# sdmmc_secure register map
Vendor: Texas Instruments
Registers are 32-bit, access per field, reset 0x0 unless marked. A register's access mark holds for its fields unless they carry their own. Offsets are as the file gives them; [hi:lo] are bit positions; {n}, {i} and the like mark numbered series; 'fields as' and 'values as' point back to an identical list.

## sdmmc_secure (part 2 of 2)
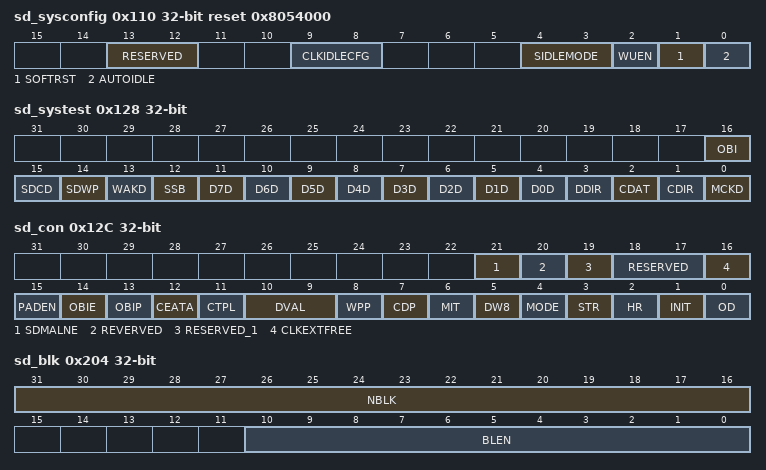
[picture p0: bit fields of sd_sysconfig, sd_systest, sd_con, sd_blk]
0x110 sd_sysconfig reset 0x8054000 (reset mask 0xFFFFC000) — This register allows controlling various parameters of the OCP interface.
  [13:12] RESERVED rw — Host interface power Management, standby/wait control. Note: these bit fields are *not used*, since the IP not support MDMA.
  [9:8] CLKIDLECFG rw — Clock idle policy register, Clocks activity during wake up mode period. Bit8: OCP interface clock Bit9: Functional clock
    0=OFF (Interface and Functional clock may be switched off); 1=INT (Interface clock is maintained. Functional clock may be switched-off.); 2=FUNC (Functional clock is maintained. Interface clock may be switched-off.); 3=ALL (Interface and Functional clocks are maintained.)
  [4:3] SIDLEMODE rw — Power management We are using this register only to change CON.DVAL, else these bit fields are *not used*, since Idle request is not supported.
  [2] WUEN rw — This field controls the wakeup capability of the module.
    0=OFF (Wakeup capability is disabled); 1=EN (Wakeup capability is enabled)
  [1] SOFTRST rw — Software reset. The bit is automatically reset by the hardware. During reset, it always returns 0.
  [0] AUTOIDLE rw — Internal Clock gating strategy 0: Clocks are free-running 1: Automatic clock gating strategy is applied, based on the OCP and MMC interface activity
    0=OFF (Clocks are free-running); 1=ON (Automatic clock gating strategy is applied)
0x114 sd_sysstatus ro — This register provides status information about the module excluding the interrupt status information.
  [0] RSTDONE — Internal Reset Monitoring Note: The debounce clock , the interface clock and the functional clock must be provided to the SDMMC host controller to allow the internal reset monitoring.
    0=ONGOING (Internal module reset is on-going); 1=COMPLETE (Reset completed)
0x124 sd_csre rw — Card Status Response Error Detection This register enables the host controller to detect card status errors of response type R1, R1b for all cards and of R5, R5b and R6 response for cards types SD or SDIO. When a bit SD_SD_CSRE[i] is set to 1, if the corresponding bit at the same position in the response RSP10[i] is set to 1, the host controller indicates a card error (SD_STAT.CERR bit) interrupt status to avoid the host driver reading the response register (RSP10). No automatic card error detection for autoCMD12 is implemented; the host system has to check autoCMD12 response register (RSP76) for possible card errors.
  [31:0] STA — Card status response error
    0=MINIMUM (Minimum value); 0xFFFFFFFF=MAXIMUM (Maximum value)
0x128 sd_systest — SDMMC System Test Register This register is used to control the signals that connect to I/O pins when the module is configured in system test (SD_SYSTEST) mode for boundary connectivity verification. In SD_SYSTEST mode, a write into SD_CMD register will not start a transfer.
  [16] OBI ro — Out-Of-Band Interrupt (OBI) data value Note: Out-Of-Band Interrupt (OBI) is not supported.
  [15] SDCD ro — Card detect input signal (SDCD) data value
    0=LOW (The card detect pin is driven low); 1=HIGH (The card detect pin is driven high)
  [14] SDWP ro — Write protect input signal (SDWP) data value
    0=LOW (The write protect pin SDWP is driven low); 1=HIGH (The write protect pin SDWP is driven high)
  [13] WAKD rw — Wake request output signal data value
    0=LOW (The pin SWAKEUP is driven low); 1=HIGH (The pin SWAKEUP is driven high)
  [12] SSB rw — Set status bit This bit must be cleared prior attempting to clear a status bit of the interrupt status register (SD_STAT).
    0=LOW (Clears this SSB bit field. Writing 0 does not clear already set status bits); 1=HIGH (Force to 1 all status bits of the interrupt status register (SD_STAT) only if the corresponding bit field in the Interrupt signal enable register (SD_ISE) is set.)
  [n+4] D{n}D rw (n=0..7) — DAT{n} input/output signal data value
    0=LOW (If SD_SYSTEST.DDIR bit = 0 (output mode direction), the DAT{n} line is driven low. If SD_SYSTEST.DDIR bit = 1 (input mode direction), no effect.); 1=HIGH (If SD_SYSTEST.DDIR bit = 0 (output mode direction), the DAT{n} line is driven high. If SD_SYSTEST.DDIR bit = 1 (input mode direction), no effect.)
  [3] DDIR rw — Control of the DAT[7:0] pins direction
    0=OUT (The DAT lines are outputs (host to card)); 1=IN (The DAT lines are inputs (card to host))
  [2] CDAT rw — CMD input/output signal data value
    0=LOW (If SD_SYSTEST.CDIR bit = 0 (output mode direction), the CMD line is driven low. If SD_SYSTEST.CDIR bit = 1 (input mode direction), no effect.); 1=HIGH (If SD_SYSTEST.CDIR bit = 0 (output mode direction), the CMD line is driven high. If SD_SYSTEST.CDIR bit = 1 (input mode direction), no effect.)
  [1] CDIR rw — Control of the CMD pin direction
    0=OUT (The CMD line is an output (host to card)); 1=IN (The CMD line is an input (card to host))
  [0] MCKD rw — MMC clock output signal data value
    0=LOW (The output clock is driven low); 1=HIGH (The output clock is driven high)
0x12C sd_con reset not defined — SDMMC Configuration Register. This register is used: - to select the functional mode or the SYSTEST mode for any card. - to send an initialization sequence to any card. - to enable the detection on DAT[1] of a card interrupt for SDIO cards only. and also to configure : - specific data and command transfers for MMC cards only. - the parameters related to the card detect and write protect input signals.
  [21] SDMALNE rw — Peripheral DMA Level/Edge Request The waveform of the DMA request can be configured either edge sensitive with early de-assertion on first access to SD_DATA register or late de-assertion, request remains active until last allowed data written into SD_DATA.
    0=EDGE (peripheral DMA edge sensitive); 1=LEVEL (peripheral DMA level sensitive)
  [20] REVERVED rw — DMA Master or Slave selection Note: these bit fields are *not used*, since the IP not support MDMA.
  [19] RESERVED_1 rw — Dual Data Rate mode Note: these bit fields are *not used*, Only Standard mode is supported.
  [18:17] RESERVED rw — Note: these bit fields are *not used*.
  [16] CLKEXTFREE rw — External clock free running This register is used to maintain card clock out of transfer transaction to enable peripheral module (for example to generate a synchronous interrupt on mmc_dat[1] ). The Clock will be maintained only if SD_SYSCTL.CEN bit is set.
    0=OFF (External card clock is cut off outside active transaction period); 1=ON (External card clock is maintained even out of active transaction period only if SD_SYSCTL.CEN bit is set.)
  [15] PADEN rw — Control Power for MMC Lines. Note: Power control is not supported using this bit.
    0=MIN (Minimum value); 1=MAX (Maximum value)
  [14] OBIE rw — Out-of-Band Interrupt Enable. Note: The Out-of-Band (OBI) interrupt is not supported.
    0=MIN (Minimum value); 1=MAX (Maximum value)
  [13] OBIP rw — Out-of-Band Interrupt Polarity Note: The Out-of-Band (OBI) interrupt is not supported.
    0=MIN (Minimum value); 1=MAX (Maximum value)
  [12] CEATA rw — CE-ATA control mode (MMC cards compliant with CE-ATA) This bit is used to indicate that next commands are considered as specific CE-ATA commands that potentially use 'command completion' features.
    0=STANDARD (Standard MMC/SD/SDIO mode); 1=CEATA (CE-ATA mode. Next commands are considered as CE-ATA commands.)
  [11] CTPL rw — Control Power for DAT[1] line MMC and SD cards: By default, this bit is set to 0 and the host controller automatically disables all the input buffers outside of a transaction to minimize the leakage current. SDIO cards: When this bit is set to 1, the host controller automatically disables all the input buffers except the buffer of DAT[1] outside of a transaction in order to detect asynchronous card interrupt on DAT[1] line and minimize the leakage current of the buffers.
    0=ALL (Disable all the input buffers outside of a transaction); 1=NOTDAT1 (Disable all the input buffers except the buffer of DAT[1] outside of a transaction)
  [10:9] DVAL rw — Debounce filter value (all cards) This register is used to define a debounce period to filter the card detect input signal (SDCD). The usage of the card detect input signal (SDCD) is optional and depends on the system integration and the type of the connector housing that accommodates the card.
    0=DEB0 (33 us debounce period); 1=DEB1 (231 us debounce period); 2=DEB2 (1 ms debounce period); 3=DEB3 (8.4 ms debounce period)
  [8] WPP rw — Write protect polarity For SD and SDIO cards only This bit selects the active level of the write protect input signal (SDWP). The usage of the write protect input signal (SDWP) is optional and depends on the system integration and the type of the connector housing that accommodates the card.
    0=LOW (Active low level); 1=HIGH (Active high level)
  [7] CDP rw — Card detect polarity All cards This bit selects the active level of the card detect input signal (SDCD). The usage of the card detect input signal (SDCD) is optional and depends on the system integration and the type of the connector housing that accommodates the card.
    0=LOW (Active low level); 1=HIGH (Active high level)
  [6] MIT rw — MMC interrupt command (MMC cards only). This bit must be set to 1, when the next write access to the command register (SD_CMD) is for writing a MMC interrupt command (CMD40) requiring the command timeout detection to be disabled for the command response.
    0=OFF (MMC interrupt command not possible, command timeout enabled); 1=ON (MMC interrupt command possible, Command timeout disabled)
  [5] DW8 rw — 8-bit mode MMC select (MMC cards only) For SD/SDIO cards, this bit must be cleared to 0. For MMC card, this bit must be set following a valid SWITCH command (CMD6) with the correct value and extend CSD index written in the argument. Prior to this command, the MMC card configuration register (CSD and EXT_CSD) must be verified for compliancy with MMC standard specification.
    0=_1OR4BIT (1-bit or 4-bit data width); 1=_8BIT (Open drain or broadcast host response)
  [4] MODE rw — Mode select (all cards) This bit selects the functional mode.
    0=FUNC (Functional mode. Transfers to the MMC/SD/SDIO cards follow the card protocol. The MMC clock is enabled. MMC/SD transfers are operated under the control of the SD_CMD register.); 1=SYSTST (SYSTEST mode. The signal pins are configured as general-purpose input/output and the 1024-byte buffer is configured as a stack memory accessible only by the local host or system DMA. The pins retain their default type (input, output or inout). SYSTEST mode is operated under the control of the SD_SYSTEST register.)
  [3] STR rw — Stream command (MMC cards only) This bit must be set to 1 only for the stream data transfers (read or write) of the adtc commands. Stream read is a class 1 command (CMD11READ_DAT_UNTIL_STOP). Stream write is a class 3 command (CMD20WRITE_DAT_UNTIL_STOP).
    0=BLOCK (Block oriented data transfer); 1=STREAM (Stream oriented data transfer)
  [2] HR rw — Broadcast host response (MMC cards only) This register is used to force the host to generate a 48-bit response for bc command type. It can be used to terminate the interrupt mode by generating a CMD40 response by the core. In order to have the host response to be generated in open drain mode, the IO must be configured accordingly in EXT_IOMUX. When SD_CON.CEATA bit is set to 1 and SD_ARG cleared to 0, when writing the value of 0 into SD_CMD register, the host controller performs a 'command completion signal disable' token (i.e., mmc_cmd line held to 0 during 47 cycles followed by a 1).
    0=OFF (The host does not generate a 48-bit response instead of a command); 1=ON (The host generates a 48-bit response instead of a command or a command completion signal disable token)
  [1] INIT rw — Send initialization stream (all cards) When this bit is set to 1, and the card is idle, an initialization sequence is sent to the card. An initialization sequence consists of setting the mmc_cmd line to 1 during 80 clock cycles. The initialization sequence is mandatory - but it is not required to do it through this bit - this bit makes it easier. Clock divider should be set to ensure that 80 clock periods are greater than 1ms. Note: In this mode, there is no command sent to the card and no response is expected. A command complete interrupt will be generated once the initialization sequence is completed.
    0=OFF (The host does not send an initialization sequence); 1=ON (The host sends an initialization sequence)
  [0] OD rw — Card open drain mode This bit must be set to 1 for MMC card commands 1, 2, 3 and 40, and if the MMC card bus is operating in open-drain mode during the response phase to the command sent. Typically, during card identification mode when the card is either in idle, ready or ident state. It is also necessary to set this bit to 1, for a broadcast host response (see Broadcast host response register SD_CON.HR).
    0=OFF (No Open Drain); 1=ON (Open Drain or Broadcast host response)
0x130 sd_pwcnt — SDMMC Power counter register This register is used to program a MMC counter to delay command transfers after activating the PAD power, this value depends on PAD characteristics and voltage.
  [15:0] NUMDEL rw — Power counter This register is used to introduce a delay between the PAD ACTIVE pin assertion and the command issued. 0h = No additional delay added 1h = TCF delay (card clock period) 2h = TCF x 2 delay (card clock period) FFFEh = TCF x 65534 delay (card clock period) FFFFh = TCF x 65535 delay (card clock period)
    0=MINIMUM (Minimum value of PWCNT); 0xFFFF=MAXIMUM (Maximum value of PWCNT)
0x200 sd_sdmasa rw — DMA System Address This register contains the system memory address for a SDMA transfer. When the Host Controller stops a SDMA transfer, this register shall point to the system address of the next contiguous data position. It can be accessed only if no transaction is executing (i.e., after a transaction has stopped). Read operations during transfers may return an invalid value. The Host Driver shall initialize this register before starting a SDMA transaction. After SDMA has stopped, the next system address of the next contiguous data position can be read from this register. The SDMA transfer waits at the every boundary specified by the Host SDMA Buffer Boundary in the Block Size register. The Host Controller generates DMA Interrupt to request the Host Driver to update this register. The Host Driver sets the next system address of the next data position to this register. When the most upper byte of this register (003h) is written, the Host Controller restarts the SDMA transfer. When restarting SDMA by the Resume command or by setting Continue Request in the Block Gap Control register, the Host Controller shall start at the next contiguous address stored here in the SDMA System Address register.
  [31:0] ADDR — SDMA System Address register
    values as sd_csre.STA
0x204 sd_blk — Transfer Length Configuration Register BLEN is the block size register. NBLK is the block count register. This register shall be used for any card.
  [31:16] NBLK rw — Block count for current transfer This register is enabled when Block count Enable (SD_CMD.BCE bit) is set to 1 and is valid only for multiple block transfers. Setting the block count to 0 results no data blocks being transferred. Note: The host controller decrements the block count after each block transfer and stops when the count reaches zero. This register can be accessed only if no transaction is executing (i.e., after a transaction has stopped). Read operations during transfers may return an invalid value and write operation will be ignored. 0h = Stop count 1h = 1 block 2h = 2 blocks FFFFh = 65535 blocks
    0=MINIMUM (Minimum value); 0xFFFF=MAXIMUM (Maximum value)
  [10:0] BLEN rw — Transfer block size This register is enabled when Block Count Enable (SD_CMD.BCE) is set to 1 and is valid only for multiple block transfers. It specifies the block size for block data transfers. Read operations during transfers may return an invalid value, and write operations are ignored. 0h = No data transfer 1h = 1 byte block length 2h = 2 bytes block length 3h = 3 bytes block length 1FFh = 511 bytes block length 200h = 512 bytes block length 3FFh = 1023 bytes block length 400h = 1024 bytes block length
    0=MINIMUM (Minimum value); 0x7FF=MAXIMUM (Maximum value)
0x208 sd_arg rw — Command argument register This register contains command argument specified as bit 39-8 of Command-Format. These registers must be initialized prior to sending the command itself to the card (write action into the register SD_CMD register). Only exception is for a command index specifying stuff bits in arguments, making a write unnecessary.
  [31:0] CMDARG — Command argument
    values as sd_csre.STA
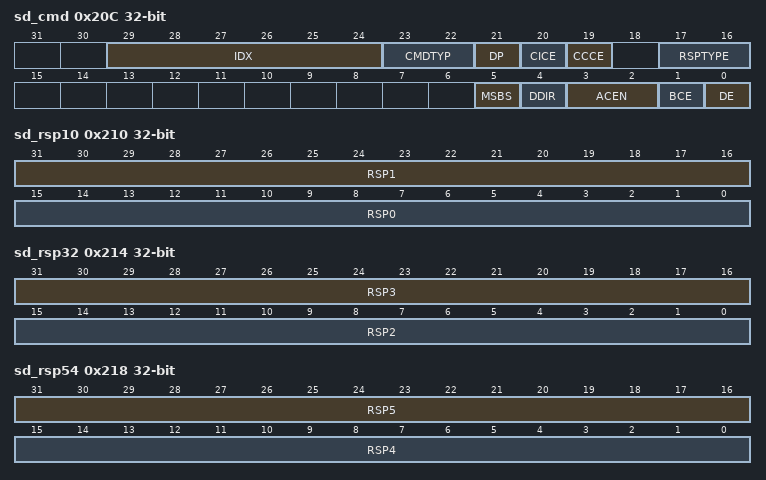
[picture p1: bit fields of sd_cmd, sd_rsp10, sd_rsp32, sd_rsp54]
0x20C sd_cmd — Command and data transfer register This register configures the data and command transfers. A write into the most significant byte send the command. A write into SD_CMD[15:0] during data transfer has no effect. This register can be used for any card. In SYSTEST mode, a write to the SD_CMD register will not start a transfer.
  [29:24] IDX rw — Command index Binary encoded value from 0 to 63 specifying the command number to send to card. Examples: - INDEX = 7h, sends CMD7 to the card - INDEX = 29h, sends CMD41 to the card
    0=MINIMUM (Minimum value); 63=MAXIMUM (Maximum value)
  [23:22] CMDTYP rw — Command type This bitfield specifies three types of special commands: - Suspend - Resume - Abort The bitfield is cleared to 0 for all other commands.
    1=SUSPEND (Upon CMD52 "Bus Suspend" operation); 0=OTHER (Others commands); 2=RESUME (Upon CMD52 "Function Select" operation); 3=ABORT (Upon CMD12 or CMD52 "I/O Abort" command)
  [21] DP rw — Data present select This register indicates that data is present and DAT line(s) shall be used. It must be cleared to 0 in the following conditions: - Command using only CMD line - Command with no data transfer but using busy signal on DAT[0] line - Resume command
    1=DAT (Command with data transfer); 0=NODAT (Command with no data transfer)
  [20] CICE rw — Command Index check enable If this bit is set to 1, the host checks the index field in the response to see if it has the same value as the command index. If it is not, it is reported as a Command Index Error. If this bit is set to 0, the Index field is not checked.
    1=ENABLE (Index check enable); 0=DISABLE (Index check disable)
  [19] CCCE rw — Command CRC check enable If this bit is set to 1, the host checks the CRC field in the response. If an error is detected, it is reported as a Command CRC Error. If this bit is set to 0, the CRC field is not checked.
    1=ENABLE (CRC field check enable); 0=DISABLE (CRC field check disable)
  [17:16] RSPTYPE rw — Response type This bits defines the response type of the command.
    1=LEN136 (Response Length 136 bits); 0=NORESP (No response); 2=LEN48 (Response Length 48 bits); 3=LEN48BUSY (Response Length 48 bits with busy after response)
  [5] MSBS rw — Multi/Single block select This bit must be set to 1 for data transfer in case of multi block command. For any others command this bit must be cleared to 0.
    1=BLOCK (Multiple block); 0=SINGLE (Single block)
  [4] DDIR rw — Data transfer Direction Select This bit defines the data transfer direction
    1=READ (Data Read (card to host)); 0=WRITE (Data Write (host to card))
  [3:2] ACEN rw — Auto CMD Enable This field determines use of auto command functions. There are two methods to stop Multiple-block read and write operation (1) Auto CMD12 Enable When this field is set to 01b, the Host Controller issues CMD12 automatically when last block transfer is completed. Auto CMD12 error is indicated to the Auto CMD Error Status register. The Host Driver shall not set this bit if the command does not require CMD12. In particular, secure commands defined in the Part 3 File Security specification do not require CMD12. (2) Auto CMD23 Enable When this bit field is set to 10b, the Host Controller issues a CMD23 automatically before issuing a command specified in the Command Register. The Host Controller Version 3.00 and later shall support this function. The following conditions are required to use the Auto CMD23. - Auto CMD23 Supported (Host Controller Version is 3.00 or later) - A memory card that supports CMD23 (SCR[33]=1) - If DMA is used, it shall be ADMA. - Only when CMD18 or CMD25 is issued (Note, the Host Controller does not check command index.) Auto CMD23 can be used with or without ADMA. By writing the Command register, the Host Controller issues a CMD23 first and then issues a command specified by the Command Index in Command register. If response errors of CMD23 are detected, the second command is not issued. A CMD23 error is indicated in the Auto CMD Error Status register. 32-bit block count value for CMD23 is set to SDMA System Address / Argument 2 register.
    1=ENA12 (Auto CMD12 enable or CCS detection enabled); 0=DISABLE (Auto CMD12 disable); 2=ENA23 (Auto CMD23 enable)
  [1] BCE rw — Block Count Enable This bit is used to enable the Block count register, which is only relevant for multiple block transfers. When this bit is 0, the Block Count register is disabled, which is useful in executing an infinite transfer.
    1=ENABLE (Block count enabled for multiple block transfer with known number of blocks); 0=DISABLE (Block count disabled for infinite transfer)
  [0] DE rw — DMA enable DMA can be enabled only if DMA Support bit in the Capabilities register is set. If this bit is set to 1, a DMA operation starts when the host writes to the upper byte of Command register (00Fh).
    1=ENABLE (DMA mode enable); 0=DISABLE (DMA mode disable)
0x210 sd_rsp10 ro — Response register 10 This 32-bit register holds bits positions [31:0] of command response type R1, R1b, R2, R3, R4, R5, R5b or R6.
  [31:16] RSP1 — Command Response [31:16]
    0=MINIMUM (Minimum value); 0xFFFF=MAXIMUM (Maximum value)
  [15:0] RSP0 — Command Response [15:0]
    0=MINIMUM (Minimum value); 0xFFFF=MAXIMUM (Maximum value)
0x214 sd_rsp32 ro — Response register 32 This 32-bit register holds bits positions [63:32] of command response type R2.
  [31:16] RSP3 — Command Response [63:48]
    0=MINIMUM (Minimum value); 0xFFFF=MAXIMUM (Maximum value)
  [15:0] RSP2 — Command Response [47:32]
    0=MINIMUM (Minimum value); 0xFFFF=MAXIMUM (Maximum value)
0x218 sd_rsp54 ro — Response register 54 This 32-bit register holds bits positions [95:64] of command response type R2.
  [31:16] RSP5 — Command Response [95:80]
    0=MINIMUM (Minimum value); 0xFFFF=MAXIMUM (Maximum value)
  [15:0] RSP4 — Command Response [79:64]
    0=MINIMUM (Minimum value); 0xFFFF=MAXIMUM (Maximum value)
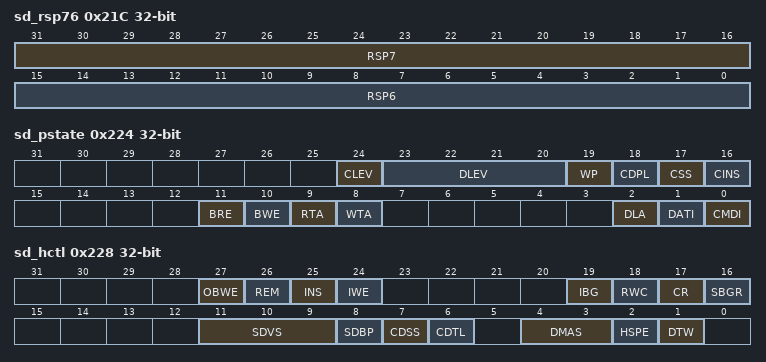
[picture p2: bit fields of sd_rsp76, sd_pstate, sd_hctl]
0x21C sd_rsp76 ro — Response register 76 This 32-bit register holds bits positions [127:96] of command response type R2.
  [31:16] RSP7 — Command Response [127:112]
    0=MINIMUM (Minimum value); 0xFFFF=MAXIMUM (Maximum value)
  [15:0] RSP6 — Command Response [111:96]
    0=MINIMUM (Minimum value); 0xFFFF=MAXIMUM (Maximum value)
0x220 sd_data rw — Data register This register is the 32-bit entry point of the buffer for read or write data transfers. The buffer size is 32bits x 256 (1024 bytes). Bytes within a word are stored and read in little endian format. This buffer can be used as two 512 byte buffers to transfer data efficiently without reducing the throughput. Sequential and contiguous access is necessary to increment the pointer correctly. Random or skipped access is not allowed. If the local host accesses this register byte-wise or 16bit-wise, the least significant byte (bits [7:0]) must always be written/read first. The update of the buffer address is done on the most significant byte write.
  [31:0] VAL — Buffer data register In functional mode (SD_CON.MODE = FUNC): - a read access to this register is allowed only when the buffer read enable status is set to 1 (SD_PSTATE.BREN), otherwise a bad access (SD_STAT.BADA) is signaled. - a write access to this register is allowed only when the buffer write enable status is set to 1 (SD_PSTATE.BWEN), otherwise a bad access (SD_STAT.BADA) is signaled and the data is not written.
    values as sd_csre.STA
0x224 sd_pstate ro — SDMMC controller status register The host can get the status of the SDMMC controller from this 32-bit read only register.
  [24] CLEV — Command line signal level This status is used to check the CMD line level to recover from errors, and for debugging.
    0=LOW (The mmc_cmd line level is 0); 1=HIGH (The mmc_cmd line level is 1)
  [23:20] DLEV — DATA line 0 to 3 signal level Bit 3 reflects DATA[3] signal level. Bit 2 reflects DATA[2] signal level. Bit 1 reflects DATA[1] signal level. Bit 0 reflects DATA[0] signal level. This status is used to check DAT line level to recover from errors, and for debugging. This is especially useful in detecting the busy signal level from DAT[0].
    0=MINIMUM (Minimum value); 15=MAXIMUM (Maximum value)
  [19] WP — Write Protect This bit reflects the write protect input pin (SDWP) level.
    1=NOPROTECT (The card is not write protected Note: SD_CON.WPP need to reflect the correct active setting of the write protect input signal (SDWP).); 0=PROTECT (The card is write protected. Note: SD_CON.WPP need to reflect the correct active setting of the write protect input signal (SDWP).)
  [18] CDPL — Card Detect Pin Level This bit reflects the inverse value of the card detect input pin (SDCD).
    1=LOW (The value of the card detect input pin (SDCD) is 0); 0=HIGH (The value of the card detect input pin (SDCD) is 1)
  [17] CSS — Card State Stable This bit is used for testing. It is set to 1 only when Card Detect Pin Level is stable (SD_PSTATE.CPDL). Debouncing is performed on the card detect input pin (SDCD) to detect card stability. This bit is not affected by software reset.
    1=STABLE (Card detect pin level is stable); 0=DEBOUNCE (Card detect pin level is debouncing)
  [16] CINS — Card inserted This bit is the debounced value of the card detect input pin (SDCD). An inactive to active transition of the card detect input pin (SDCD) will generate a card insertion interrupt (SD_STAT.CINS). An active to inactive transition of the card detect input pin (SDCD) will generate a card removal interrupt (SD_STAT.REM). This bit is not affected by a software reset.
    1=CARD (Card is detected Note: SD_CON.CDP need to reflect the correct active level of the write protect input signal (SDCD).); 0=NOCARD (No card is detected Note: SD_CON.CDP need to reflect the correct active level of the write protect input signal (SDCD).)
  [11] BRE — Buffer read enable This bit is used for non-DMA read transfers. This read only flag indicates that valid data exists in the host side buffer status. If this bit is 1, readable data exists in the buffer. A change of this bit from 1 to 0 occurs when all the block data is read from the buffer. A change of this bit from 0 to 1 occurs when all the block data is ready in the buffer and generates the Buffer Read Ready Interrupt.
    1=ENABLE (Read BLEN bytes enable. Readable data exists in the buffer.); 0=DISABLE (Read BLEN bytes disable)
  [10] BWE — Buffer write enable This status is used for non-DMA write transfers. This read only flag indicates if space is available for write data. If this bit is 1, data can be written to the buffer. A change of this bit from 1 to 0 occurs when all the block data is written to the buffer. A change of this bit from 0 to 1 occurs when top of block data can be written to the buffer and generates the Buffer Write Ready Interrupt.
    1=SPACE (There is enough space in the buffer to write BLEN bytes of data); 0=NOSPACE (There is no room left in the buffer to write BLEN bytes of data.)
  [9] RTA — Read transfer active (SD mode only) This status is used for detecting completion of a read transfer. This bit is set to 1 for either of the following conditions: - After the end bit of the read command - When writing a 1 to continue Request in the Block Gap Control register to restart a read transfer This bit is cleared to 0 for either of the following conditions: - When the last data block as specified by block length is transferred to the system. - When all valid data blocks have been transferred to the system and no current block transfers are being sent as a result of the Stop At Block Gap Request set to 1. A transfer complete interrupt is generated when this bit changes to 0.
    1=ACTIVE (Read data transfer on going); 0=NODATA (No valid data)
  [8] WTA — Write transfer active This status indicates a write transfer active. If this bit is 0, it means no valid write data exists. This bit is set in either of the following cases: - After the end bit of the write command. - When writing a 1 to Continue Request in the Block Gap Control register to restart a write transfer. This bit is cleared in either of the following cases: - After getting the CRC status of the last data block as specified by the transfer count (Single or Multiple) - After getting a CRC status of any block where data transmission is about to be stopped by a Stop At Block Gap Request. During a write transaction, a Block Gap Event interrupt is generated when this bit is changed to 0, as a result of the Stop At Block Gap Request being set. This status is useful for the host to determine when to issue commands during write busy.
    1=ACTIVE (Write data transfer on going); 0=NODATA (No valid data)
  [2] DLA — DATA Line Active (SD Mode only) This bit indicates whether one of the DATA lines on SD bus is in use.
    1=ACTIVE (mmc_data line active); 0=INACTIVE (mmc_data line inactive)
  [1] DATI — Command Inhibit (DAT) (SD Mode Only) This status bit is generated if either the DAT Line Active or the Read transfer Active is set to 1. If this bit is 0, it indicates the host can issue the next SD command. Commands with busy signal belong to Command Inhibit (DAT) (ex. R1b, R5b type). Changing from 1 to 0 generates a Transfer Complete interrupt. Note: The SD Host Driver can save registers in the range of 000-00Dh for a suspend transaction after this bit has changed from 1 to 0.
    1=NOTALLOWED (Issuing of command using DAT lines is not allowed); 0=ALLOWED (Issuing of command using the DAT lines is allowed)
  [0] CMDI — Command Inhibit (CMD) (SD Mode Only) If this bit is 0, it indicates the CMD line is not in use and the host can issue a SD command using the CMD line. This bit is set immediately after the Command register (00Fh) is written. This bit is cleared when the command response is received. Even if the Command Inhibit (DAT) is set to 1, Commands using only the CMD line can be issued if this bit is 0. Changing from 1 to 0 generates a Command complete interrupt. If the host cannot issue the command because of a command conflict error or because of Command Not Issued By Auto CMD12 Error, this bit shall remain 1 and the Command Complete is not set. Status issuing Auto CMD12 is not read from this bit. Auto CMD12 and Auto CMD23 consist of two responses. In this case, this bit is not cleared by the response of CMD12 or CMD23 but cleared by the response of a read/write command. Status issuing Auto CMD12 is not read from this bit. So if a command is issued during Auto CMD12 operation, Host Controller shall manage to issue two commands: CMD12 and a command set by Command register.
    1=NOTALLOWED (Issuing of command using mmc_cmd line is not allowed); 0=ALLOWED (Issuing of command using mmc_cmd line is allowed)
0x228 sd_hctl — Host Control Register This register defines the host controls to set power, wakeup and transfer parameters. SD_HCTL[31:24] = Wakeup control SD_HCTL[23:16] = Block gap control SD_HCTL[15:8] = Power control SD_HCTL[7:0] = Host control
  [27] OBWE rw — Wakeup event enable for 'Out-of-Band' Interrupt Note: This bit has no effect since the wakeup output is unconnected Note: Out-of-Band Interrupt (OBI) is not supported
    0=MIN (Minimum value); 1=MAX (Maximum value)
  [26] REM rw — Wakeup event enable on SD card removal Note: This bit has no effect since the wakeup output is unconnected
    0=MIN (Minimum value); 1=MAX (Maximum value)
  [25] INS rw — Wakeup event enable on SD card insertion Note: This bit has no effect since the wakeup output is unconnected
    0=MIN (Minimum value); 1=MAX (Maximum value)
  [24] IWE rw — Wakeup event enable on SD card interrupt Note: This bit has no effect since the wakeup output is unconnected
    0=MIN (Minimum value); 1=MAX (Maximum value)
  [19] IBG rw — Interrupt block at gap This bit is valid only in 4-bit mode of SDIO card to enable interrupt detection in the interrupt cycle at block gap for a multiple block transfer. For MMC cards and for SD card this bit should be cleared to 0.
    0=DISABLE (Disable interrupt detection at the block gap in 4-bit mode); 1=ENABLE (Enable interrupt detection at the block gap in 4-bit mode)
  [18] RWC rw — Read wait control The read wait function is optional only for SDIO cards. If the card supports read wait, this bit must be enabled, then requesting a stop at block gap (SD_HCTL.SBGR) generates a read wait period after the current end of block. Note: If read wait is not supported it may cause a conflict on mmc_dat line.
    0=DISABLE (Disable read wait control. Suspend/resume cannot be supported); 1=ENABLE (Enable read wait control)
  [17] CR rw — Continue request This bit is used to restart a transaction that was stopped by requesting a stop at block gap (SD_HCTL[16] SBGR bit). Set this bit to 1 restarts the transfer. The bit is automatically cleared to 0 by the host controller when transfer has restarted, that is, mmc_dat line is active (SD_PSTATE.DLA) or transferring data (SD_PSTATE.WTA). The Stop at block gap request must be disabled (SD_HCTL[16] SBGR bit =0) before setting this bit.
    0=NOEFFECT; 1=RESTART (Transfer restart)
  [16] SBGR rw — Stop at block gap request This bit is used to stop executing a transaction at the next block gap. The transfer can restart with a continue request (SD_HCTL.CR) or during a suspend/resume sequence. In case of read transfer, the card must support read wait control. In case of write transfer, the host driver must set this bit after all block data written. Until the transfer completion (SD_STAT.TC bit set to 1), the host driver must leave this bit set to 1. If this bit is set, the local host may not write to the data register (DATA).
    0=TRANS (Transfer mode); 1=STOP (Stop at block gap)
  [11:9] SDVS rw — SD bus voltage select (All cards). The host driver should set these bits to select the voltage level for the card according to the voltage supported by the system (SD_CAPA[26] VS18 bit, SD_CAPA[25] VS30 bit, SD_CAPA[24] VS33 bit) before starting a transfer.
    6=MID (3.0V (Typical)); 5=LOW (1.8V (Typical)); 7=HIGH (3.3V (Typical))
  [8] SDBP rw — SD bus power. Before setting this bit, the host driver shall select the SD bus voltage (SD_HCTL[11:9] SDVS bits). If the host controller detects the No card state, this bit is automatically cleared to 0. If the module is power off, a write in the command register (SD_CMD) will not start the transfer. A write to this bit has no effect if the selected SD bus voltage is not supported according to capability register (SD_CAPA[26] VS18 bit, SD_CAPA[25] VS30 bit or SD_CAPA[24] VS33 bit).
    0=OFF (Power off); 1=ON (Power on)
  [7] CDSS rw — Card Detect Signal Selection This bit selects the source for the card detection. When the source for the card detection is switched, the Card insertion and removal interrupts should be disabled to avoid unexpected interrupts. In Card Detect Test Level mode, the card insertion and removal signal can be controlled by SD_HCTL.CDTL.
    0=SDCD (SDCD signal is selected (for normal use)); 1=TEST (The Card Detect Test Level is selected (for test purposes))
  [6] CDTL rw — Card Detect Test Level This bit is only functional when the Card Detect Signal Selection selects the Card Detect Test Level mode (SD_HCTL.CDSS = 1).
    0=NOCARD; 1=CARD (Card inserted)
  [4:3] DMAS rw — DMA Select Mode Note: This functionality is not is not supported, since MADMA_EN = 0 by design.
    0=MINIMUM (Minimum value); 3=MAX (Maximum value)
  [2] HSPE rw — High Speed Enable Before setting this bit, the Host Driver shall check the High Speed Support in the Capabilities register. If this bit is cleared to 0 (default), the Host Controller outputs CMD line and DAT lines at the falling edge of the SD Clock. If this bit is set to 1, the Host Controller outputs CMD line and DAT lines at the rising edge of the SD Clock.
    0=NOMAL (Normal speed mode); 1=HIGH (High speed mode)
  [1] DTW rw — Data transfer width This bit must be set following a valid SET_BUS_WIDTH command (ACMD6) with the value written in bit 1 of the argument. Prior to this command, the SD card configuration register (SCR) must be verified for the supported bus width by the SD card.
    0=WIDTH_1 (1-bit Data width (mmc_dat0 used)); 1=WIDTH_4 (4-bit Data width (mmc_dat[3:0] used))
